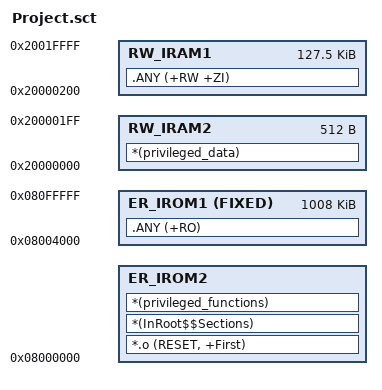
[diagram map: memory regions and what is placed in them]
; *************************************************************
; *** Scatter-Loading Description File generated by uVision ***
; *************************************************************

LR_IROM1 0x08000000 0x00200000  { ; load region size_region
  ER_IROM2 0x08000000   { 
   *.o (RESET, +First)
   *(InRoot$$Sections)  ; load address = execution address 
   *(privileged_functions)
  }
  ER_IROM1 0x08004000 FIXED  0x000FC000{  ; load address = execution address

   .ANY (+RO)
  }
  
   RW_IRAM2 0x20000000 0x00000200  {  ; RW data
   *(privileged_data)
   }
  RW_IRAM1 0x20000200 0x00001FE00  {  ; RW data
   .ANY (+RW +ZI)
  }
  
}
